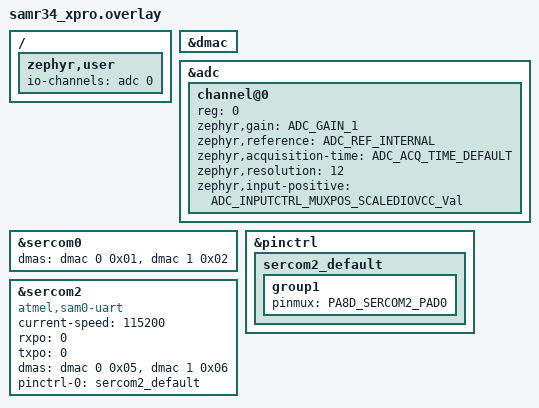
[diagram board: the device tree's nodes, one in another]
/*
 * Copyright (c) 2022 Kumar Gala <galak@kernel.org>
 *
 * SPDX-License-Identifier: Apache-2.0
 */


tst_dma0: &dmac {
	status = "okay";
};

#define ADC_INPUTCTRL_MUXPOS_SCALEDIOVCC_Val 0x1BU

/ {
	zephyr,user {
		io-channels = <&adc 0>;
	};
};

&adc {
	#address-cells = <1>;
	#size-cells = <0>;
	channel@0 {
		reg = <0>;
		zephyr,gain = "ADC_GAIN_1";
		zephyr,reference = "ADC_REF_INTERNAL";
		zephyr,acquisition-time = <ADC_ACQ_TIME_DEFAULT>;
		zephyr,resolution = <12>;
		zephyr,input-positive = <ADC_INPUTCTRL_MUXPOS_SCALEDIOVCC_Val>;
	};
};

&dmac {
	status = "okay";
};

&sercom0 {
	dmas = <&dmac 0 0x01>, <&dmac 1 0x02>;
	dma-names = "rx", "tx";
};

&pinctrl {
	sercom2_default: sercom2_default {
		group1 {
			pinmux = <PA8D_SERCOM2_PAD0>;
		};
	};
};

dut: &sercom2 {
	status = "okay";
	compatible = "atmel,sam0-uart";
	current-speed = <115200>;
	rxpo = <0>;
	txpo = <0>;
	dmas = <&dmac 0 0x05>, <&dmac 1 0x06>;
	dma-names = "rx", "tx";
	pinctrl-0 = <&sercom2_default>;
	pinctrl-names = "default";
};
